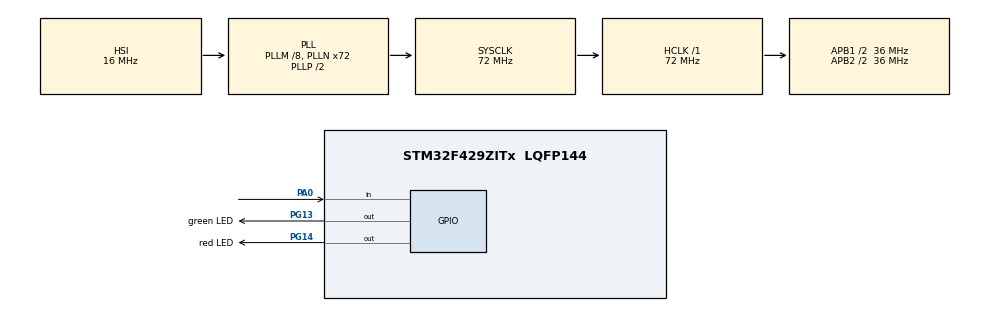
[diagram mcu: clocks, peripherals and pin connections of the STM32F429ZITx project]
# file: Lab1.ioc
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Mcu.Family=STM32F4
Mcu.Name=STM32F429ZITx
Mcu.Package=LQFP144
NVIC.PriorityGroup=NVIC_PRIORITYGROUP_4
PA0/WKUP.Signal=GPIO_Input
PG13.GPIO_Label=green LED
PG13.Signal=GPIO_Output
PG14.GPIO_Label=red LED
PG14.Signal=GPIO_Output
ProjectManager.HeapSize=0x200
ProjectManager.StackSize=0x400
ProjectManager.TargetToolchain=STM32CubeIDE
RCC.48MHZClocksFreq_Value=48000000
RCC.AHBFreq_Value=72000000
RCC.APB1CLKDivider=RCC_HCLK_DIV2
RCC.APB1Freq_Value=36000000
RCC.APB1TimFreq_Value=72000000
RCC.APB2CLKDivider=RCC_HCLK_DIV2
RCC.APB2Freq_Value=36000000
RCC.APB2TimFreq_Value=72000000
RCC.CortexFreq_Value=72000000
RCC.HCLKFreq_Value=72000000
RCC.HSE_VALUE=8000000
RCC.HSI_VALUE=16000000
RCC.LSE_VALUE=32768
RCC.PLLM=8
RCC.PLLN=72
RCC.PLLQ=3
RCC.PLLSAIN=50
RCC.SYSCLKFreq_VALUE=72000000
RCC.SYSCLKSource=RCC_SYSCLKSOURCE_PLLCLK
RCC.VCOOutputFreq_Value=144000000
board=STM32F429I-DISC1

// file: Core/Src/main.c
/* USER CODE BEGIN Header */
/**
  ******************************************************************************
  * @file           : main.c
  * @brief          : Main program body
  ******************************************************************************
  * @attention
  *
  * Copyright (c) 2026 STMicroelectronics.
  * All rights reserved.
  *
  * This software is licensed under terms that can be found in the LICENSE file
  * in the root directory of this software component.
  * If no LICENSE file comes with this software, it is provided AS-IS.
  *
  ******************************************************************************
  */
/* USER CODE END Header */
#include "main.h"

void SystemClock_Config(void);
static void MX_GPIO_Init(void);

int main(void)
{

  /* USER CODE BEGIN 1 */
	// Variable for Task 2
	int i = 0;
	// Variables for Task 3
	uint8_t button_state = 0;
	uint8_t last_button_state = 0;
	// Variables for Task 4
	uint32_t half_period = 500;
	uint32_t last_blink_time = 0;
	uint8_t last_btn_state = GPIO_PIN_RESET;
  /* USER CODE END 1 */

  /* MCU Configuration--------------------------------------------------------*/

  /* Reset of all peripherals, Initializes the Flash interface and the Systick. */
  HAL_Init();

  /* Configure the system clock */
  SystemClock_Config();

  /* Initialize all configured peripherals */
  MX_GPIO_Init();

  /* Infinite loop */
  /* USER CODE BEGIN WHILE */
  while (1)
  {
	  // Lab 1, version 4

	  // TASK 1: 3, 2, 1 binary combination
	  /*
	  HAL_GPIO_WritePin(GPIOG, green_LED_Pin, GPIO_PIN_SET);
	  HAL_GPIO_WritePin(GPIOG, red_LED_Pin, GPIO_PIN_SET);
	  HAL_Delay(1000);
	  HAL_GPIO_WritePin(GPIOG, red_LED_Pin, GPIO_PIN_RESET);
	  HAL_Delay(1000);
	  HAL_GPIO_WritePin(GPIOG, green_LED_Pin, GPIO_PIN_RESET);
	  HAL_GPIO_WritePin(GPIOG, red_LED_Pin, GPIO_PIN_SET);
	  HAL_Delay(1000);
	  */

	  // TASK 2: red led flash every 1 second, green led flash every 4 second
	  /*
	  for (i = 0; i < 4; i++) {
		  HAL_GPIO_WritePin(GPIOG, red_LED_Pin, GPIO_PIN_SET);
		  if (i == 0) {
			  HAL_GPIO_WritePin(GPIOG, green_LED_Pin, GPIO_PIN_SET);
		  }
		  HAL_Delay(500);
		  HAL_GPIO_WritePin(GPIOG, red_LED_Pin, GPIO_PIN_RESET);
		  HAL_GPIO_WritePin(GPIOG, green_LED_Pin, GPIO_PIN_RESET);
		  HAL_Delay(500);
	  }
	  */

	  // TASK 3: green LED shine with user button
	  /*
	  button_state = HAL_GPIO_ReadPin (GPIOA, GPIO_PIN_0);
	  if (button_state == GPIO_PIN_RESET && last_button_state == GPIO_PIN_SET) {
		  HAL_GPIO_TogglePin(GPIOG, GPIO_PIN_13);
		  HAL_Delay(50);
	  }
	  last_button_state = button_state;
	  */

	  // TASK 4: red LED blinking with different frequency
	  // 1. Check for Button Press (Rising Edge Detection)
	  /*
	  uint8_t current_btn_state = HAL_GPIO_ReadPin(GPIOA, GPIO_PIN_0);

	  if (current_btn_state == GPIO_PIN_SET && last_btn_state == GPIO_PIN_RESET) {
		  // Increase period by 0.5s -> half_period increases by 250ms
		  half_period += 250;

		  // Simple debounce to prevent one click counting as five
		  HAL_Delay(50);
	  }
	  last_btn_state = current_btn_state;

	  // 2. Non-blocking Blink Logic
	  // We check if the time elapsed is greater than our target half_period
	  if (HAL_GetTick() - last_blink_time >= half_period) {
		  HAL_GPIO_TogglePin(GPIOG, GPIO_PIN_14); // Toggle Red LED
		  last_blink_time = HAL_GetTick();        // Reset the timer
	  }
	  */
    /* USER CODE END WHILE */

  }
}

void SystemClock_Config(void)
{
  RCC_OscInitTypeDef RCC_OscInitStruct = {0};
  RCC_ClkInitTypeDef RCC_ClkInitStruct = {0};

  /** Configure the main internal regulator output voltage
  */
  __HAL_RCC_PWR_CLK_ENABLE();
  __HAL_PWR_VOLTAGESCALING_CONFIG(PWR_REGULATOR_VOLTAGE_SCALE3);

  /** Initializes the RCC Oscillators according to the specified parameters
  * in the RCC_OscInitTypeDef structure.
  */
  RCC_OscInitStruct.OscillatorType = RCC_OSCILLATORTYPE_HSI;
  RCC_OscInitStruct.HSIState = RCC_HSI_ON;
  RCC_OscInitStruct.HSICalibrationValue = RCC_HSICALIBRATION_DEFAULT;
  RCC_OscInitStruct.PLL.PLLState = RCC_PLL_ON;
  RCC_OscInitStruct.PLL.PLLSource = RCC_PLLSOURCE_HSI;
  RCC_OscInitStruct.PLL.PLLM = 8;
  RCC_OscInitStruct.PLL.PLLN = 72;
  RCC_OscInitStruct.PLL.PLLP = RCC_PLLP_DIV2;
  RCC_OscInitStruct.PLL.PLLQ = 3;
  if (HAL_RCC_OscConfig(&RCC_OscInitStruct) != HAL_OK)
  {
    Error_Handler();
  }

  /** Initializes the CPU, AHB and APB buses clocks
  */
  RCC_ClkInitStruct.ClockType = RCC_CLOCKTYPE_HCLK|RCC_CLOCKTYPE_SYSCLK
                              |RCC_CLOCKTYPE_PCLK1|RCC_CLOCKTYPE_PCLK2;
  RCC_ClkInitStruct.SYSCLKSource = RCC_SYSCLKSOURCE_PLLCLK;
  RCC_ClkInitStruct.AHBCLKDivider = RCC_SYSCLK_DIV1;
  RCC_ClkInitStruct.APB1CLKDivider = RCC_HCLK_DIV2;
  RCC_ClkInitStruct.APB2CLKDivider = RCC_HCLK_DIV2;

  if (HAL_RCC_ClockConfig(&RCC_ClkInitStruct, FLASH_LATENCY_2) != HAL_OK)
  {
    Error_Handler();
  }
}

static void MX_GPIO_Init(void)
{
  GPIO_InitTypeDef GPIO_InitStruct = {0};

  /* GPIO Ports Clock Enable */
  __HAL_RCC_GPIOA_CLK_ENABLE();
  __HAL_RCC_GPIOG_CLK_ENABLE();

  /*Configure GPIO pin Output Level */
  HAL_GPIO_WritePin(GPIOG, green_LED_Pin|red_LED_Pin, GPIO_PIN_RESET);

  /*Configure GPIO pin : PA0 */
  GPIO_InitStruct.Pin = GPIO_PIN_0;
  GPIO_InitStruct.Mode = GPIO_MODE_INPUT;
  GPIO_InitStruct.Pull = GPIO_NOPULL;
  HAL_GPIO_Init(GPIOA, &GPIO_InitStruct);

  /*Configure GPIO pins : green_LED_Pin red_LED_Pin */
  GPIO_InitStruct.Pin = green_LED_Pin|red_LED_Pin;
  GPIO_InitStruct.Mode = GPIO_MODE_OUTPUT_PP;
  GPIO_InitStruct.Pull = GPIO_NOPULL;
  GPIO_InitStruct.Speed = GPIO_SPEED_FREQ_LOW;
  HAL_GPIO_Init(GPIOG, &GPIO_InitStruct);

}

void Error_Handler(void)
{
  __disable_irq();
  while (1)
  {
  }
}
